# CYBLE_222014_01 register map
File version: 0.1
PRoC BLE
Registers are 32-bit, read-write, no defined reset value unless marked. A register's access mark holds for its fields unless they carry their own. Offsets are from the block's base; lines under a group give offsets from that group; [hi:lo] are bit positions; {n}, {i} and the like mark numbered series; 'fields as' and 'values as' point back to an identical list; <NAME> marks a mode.

## Memory map
0x00000000 Uart — Serial Communication Block
0x00000000 Pwm
0x40000000 DMAC — DMAC Registers

## Pwm
Base 0x00000000
0x400F0022 Pwm__COMPARE1 8-bit — UDB.D0 - Assigned Compare1 Value
0x400F0032 Pwm__COMPARE2 8-bit — UDB.D1 - Assigned Compare2 Value
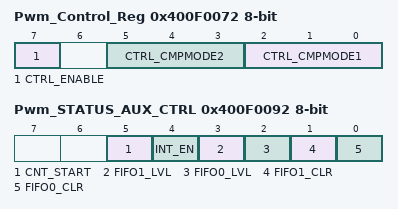
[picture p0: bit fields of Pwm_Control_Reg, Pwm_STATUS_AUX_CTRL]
0x400F0072 Pwm_Control_Reg 8-bit — UDB Control Register - Assigned Control Register Value
  [7] CTRL_ENABLE — Enable the PWM
  [5:3] CTRL_CMPMODE2 — Compare mode 2
  [2:0] CTRL_CMPMODE1 — Compare mode 1
0x400F0092 Pwm_STATUS_AUX_CTRL 8-bit — UDB Auxilliary Control Register
  [5] CNT_START — FIFO0 clear
    0=E_CNT_START0 (Disable counter); 1=E_CNT_START1 (Enable counter)
  [4] INT_EN
    0=E_INT_EN0 (Interrupt disabled); 1=E_INT_EN1 (Interrupt enabled)
  [3] FIFO1_LVL — FIFO level
    0=E_FIFO_LVL_0 (FIFO LVL: input mode: FIFO not full; output mode: FIFO not empty); 1=E_FIFO_LVL_1 (FIFO LVL: input mode: FIFO at least 1/2 empty; output mode: FIFO at least 1/2 full)
  [2] FIFO0_LVL — FIFO level
    values as FIFO1_LVL
  [1] FIFO1_CLR — FIFO1 clear
    0=E_FIFO_CLR_0 (Normal FIFO operation); 1=E_FIFO_CLR_1 (Clear FIFO state)
  [0] FIFO0_CLR — FIFO0 clear
    values as FIFO1_CLR

## DMAC — DMAC Registers
Base 0x40000000
0x101000 DMAC_CTL — DMA controller control register
  [31] ENABLED — Global DMAC enable
    0=Disabled (DMA controller is disabled.); 1=Enabled (DMA controller is enabled.)
0x101010 DMAC_STATUS — DMA controller status register
  [31] PING_PONG ro — Specifies whether the PING descriptor ('0') or PONG descriptor ('1') of the channel is currently in use.
    0=DESCR0 (Descriptor 0 (PING) is currently in use.); 1=DESCR1 (Descriptor 1 (PONG) is currently in use.)
  [31] ACTIVE ro — Specifies if there is a currently active (pending) channel in the data transfer engine.
    0=IDLE (No currently active channel.); 1=ACTIVE (Currently active channel.)
  [29:28] PRIO ro — Specifies the priority of the currently active channel.
  [26:24] STATE ro — State of the data transfer engine.
    0=IDLE (Idle state when the DMA is not active.); 1=LOAD_DESCR (The DMA is loading the descriptor to the DMA transfer engine.); 2=LOAD_SRC (The DMA is getting the value from the source location.); 3=STORE_DST (The DMA is storing the value at the destination location.); 4=STORE_DESCR (The DMA is updating the descriptors after completion of transfer.); 5=WAIT_TRIG_DEACT (The DMA is waiting for the level sensitive trigger to deactivate.); 6=STORE_ERROR (There was an error during the transaction and the DMA is writing the error code to the channel status register.)
  [20:16] CH_ADDR ro — Specifies the channel number of the currently active channel. For example, if channel 7 is active, DMAC_STATUS.ACTIVE is '1' and STATUS.CH_ADDR is '7'.
  [15:0] DATA_NR ro — Specifies the index of the currently active data transfer. This value increases from '0' to the DATA_NR field specified of the currently active descriptor control word.
0x101014 DMAC_STATUS_SRC_ADDR — Source address currently being used by the DMA controller
  [31:0] ADDR ro — The source address currently being used by the DMA transfer engine. This field is provided for debug purposes. Note while reading the DMAC_STATUS, DMAC_STATUS_SRC_ADDR and DMAC_STATUS_DST_ADDR registers, the transfer engine may have advanced after one or more of these reads. Meaning the register values may not be related to each other.
0x101018 DMAC_STATUS_DST_ADDR — Destination address currently being used by the DMA controller
  [31:0] ADDR ro — The destination address currently being used by the DMA transfer engine. This field is provided for debug purposes. Note while reading the DMAC_STATUS, DMAC_STATUS_SRC_ADDR and DMAC_STATUS_DST_ADDR registers, the transfer engine may have advanced after one or more of these reads. Meaning the register values may not be related to each other.
0x10101C DMAC_STATUS_CH_ACT — Channel activation status
  [31:0] CH ro — Channel activation status. Bit i is associated to channel i. Software reads this field to get information on all actively pending channels (either in pending or in the data transfer engine).
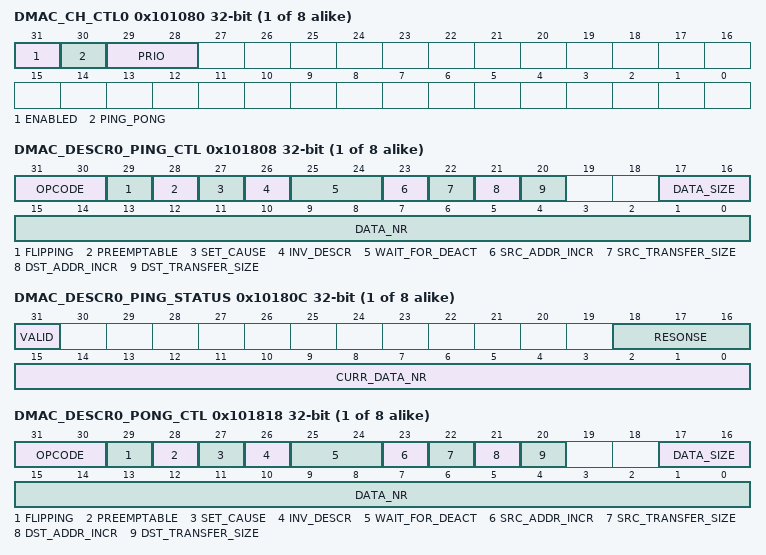
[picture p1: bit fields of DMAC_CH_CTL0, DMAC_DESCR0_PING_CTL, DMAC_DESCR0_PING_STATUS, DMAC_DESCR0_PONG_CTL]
{0x101080+4i} DMAC_CH_CTL{i} (i=0..7) — DMA channel {i} control register
  [31] ENABLED — Channel enable control.
    0=Disabled (Channel is currently disabled.); 1=Enabled (Channel is currently enabled.)
  [30] PING_PONG — Identifies the descriptor structure that is currently in use by the DMA controller.
    values as DMAC_STATUS.PING_PONG
  [29:28] PRIO — Channel priority. Priority can be 0,1,2 or 3. 0 is the highest.
0x1017F0 DMAC_INTR — Interrupt register
  [31:0] CH — Set to '1', when event is detected. Write INTR field with '1', to clear bit. Write INTR_SET field with '1', to set bit.
0x1017F4 DMAC_INTR_SET — Interrupt set register
  [31:0] CH — Write INTR_SET field with '1' to set corresponding INTR field (a write of '0' has no effect).
0x1017F8 DMAC_INTR_MASK — Interrupt mask register
  [31:0] CH — Mask for corresponding field in INTR register.
0x1017FC DMAC_INTR_MASKED — Interrupt masked register
  [31:0] CH ro — Bitwise AND between the interrupt reguest (INTR) and mask (INTR_MASK) registers.
{0x101800+0x20*i} DMAC_DESCR{i}_PING_SRC (i=0..7) — Descriptor 0 source address location for channel {i}
  [31:0] SRC — Source address.
{0x101804+0x20*i} DMAC_DESCR{i}_PING_DST (i=0..7) — Descriptor 0 destination address location for channel {i}
  [31:0] DST — Destination address.
{0x101808+0x20*i} DMAC_DESCR{i}_PING_CTL (i=0..7) — Descriptor 0 control register for channel {i}
  [31:30] OPCODE — Specifies how the DMA reacts to a trigger event.
    0=SINGLE_DATA_ELEMENT (A single trigger initiates a single data element transfer. This opcode specifies a transfer of a single data element. The current descriptor is completed when the amount of transferred single data elements equals the programmed buffer size (DATA_NR+1).); 1=ENTIRE_DESCRIPTOR (A single trigger initiates an entire descriptor transfer. This opcode specifies a transfer of DATA_NR+1 data elements as specified by the current descriptor structure. The current descriptor is completed when its data transfer is completed.); 2=ENTIRE_DESCRIPTOR_CHAIN (A single trigger initiates a descriptor list transfer. This opcode specifies a transfer of DATA_NR+1 data elements as specified by the current descriptor structure and by successive valid descriptors. The current descriptor is completed when its data transfer is completed. This OPCODE relies on FLIPPING to be set to '1', such that the CHi_CTL.PING_PONG field is flipped/inverted and the successive descriptor is used. This continues for as long as the successive descriptor is valid. Note that as the HW is using the PING/PONG descriptor, the SW can prepare the alternate PONG/PING descriptor. The interrupt mechanism is used by HW to convey to the SW that the current descriptor is completed (and can be prepared for a successive transfer).)
  [29] FLIPPING — If set, on completion of the current descriptor structure, the current descriptor identifier is flipped/inverted. In DMA mode, descriptor list transfer, flipping of the current descriptor identifier can be used to construct a linked list of descriptor structures.
  [28] PREEMPTABLE — If set, the transfer is preemptable. Multi data element transfers are constructed out of multiple single data element load (from the source location) and store (to the destination location) sequences. This field allows higher priority activated channels to preempt the current transfer in between these atomic (load, store) sequences. Preemption will NOT deactivate the current channel. As a result, after completion of a higher priority activated channel, the current channel is rescheduled.
  [27] SET_CAUSE — If set, the interrupt bit of the channel is set to '1' on completion of the current descriptor structure.
  [26] INV_DESCR — If set, the VALID bit of the descriptor's STATUS word is set to '0' on completion of the current descriptor structure.
  [25:24] WAIT_FOR_DEACT — Specifies whether the data transfer engine should wait for the channel to be deactivated; i.e. the selected system trigger is not active. This field is used to synchronize the controller's data transfer(s) with the agent that generated the trigger. This field is ONLY used at the completion of an opcode. E.g., a FIFO indicates that it is empty and it needs a new data sample. The agent removes the trigger ONLY when the data sample has been written by the transfer engine AND received by the agent. Furthermore, the agent's trigger may be delayed by a few cycles before it reaches the DW/DMA controller. This field is used for level sensitive trigger, which reflect state (pulse sensitive triggers should have this field set to '0'). The wait cycles incurred by this field reduce DW/DMA controller performance.
    0=PULSE (Do not wait for de-activation (for pulse sensitive triggers).); 1=LEVEL_FOUR (Wait for up to 4 cycles.); 2=LEVEL_EIGHT (Wait for up to 8 cycles.); 3=LEVEL_UNKNOWN (Wait indefinitely. This option may result in DMA controller lockup if the system trigger is not de-activated by the source agent.)
  [23] SRC_ADDR_INCR — Specifies whether the source address is incremented by the SRC_TRANSFER_SIZE after the transfer of each data element.
    0=INC_NONE (No address increment.); 1=INC_SRC_ADDR (Increment the source address.)
  [22] SRC_TRANSFER_SIZE — Specifies the bus transfer size to the source location.
    0=DATA_SIZE (As specified by DATA_SIZE field.); 1=WORD (Word (4 bytes).)
  [21] DST_ADDR_INCR — Specifies whether the destination address is incremented by the DST_TRANSFER_SIZE after the transfer of each data element.
    0=INC_NONE (No address increment.); 1=INC_DST_ADDR (Increment the destination address.)
  [20] DST_TRANSFER_SIZE — Specifies the bus transfer size to the destination location.
    values as SRC_TRANSFER_SIZE
  [17:16] DATA_SIZE — Specifies the data element size.
    0=BYTE (1 byte.); 1=HALFWORD (Halfword (2 bytes).); 2=WORD (Word (4 bytes).)
  [15:0] DATA_NR — Number of data elements this descriptor transfers. A value of N results in a transfer of N+1 data elements.
{0x10180C+0x20*i} DMAC_DESCR{i}_PING_STATUS (i=0..7) — Descriptor 0 status register for channel {i}
  [31] VALID — Descriptor validity status. Hardware set this field to '0' when a descriptor is done, but only if CONTROL.INV_DESCR is '1'. Software sets this field to '1' when a descriptor is initialized.
    0=INVALID (Invalid, cannot be used for a data transfer. An attempt to use this descriptor for a data transfer will result in an INVALID_DESCR response code and the interrupt cause bit is set to '1'.); 1=VALID
  [18:16] RESONSE — Response code (the first two codes NO_ERROR and DONE are the result of normal behavior, the other codes are the result of erroneous behavior).
    0=NO_ERROR (No error. Setting this response does NOT set the interrupt bit to '1'. STATUS.VALID is NOT affected. CHx_CTL.ENABLED is NOT affected. CHx_CTL.PING_PONG is not updated. This response is used for an unused or not completed descriptor. Software should set the RESPONSE field to '0'/NO_ERROR during descriptor initialization.); 1=DONE (Descriptor is done (without errors). Setting this response sets the interrupt cause bit to '1' if CONTROL.SET_CAUSE is '1'. STATUS.VALID is set to '0' if CONTROL.INV_DESCR is '1'. CHx_CTL.ENABLED is NOT affected. CHx_CTL.PING_PONG is updated if CONTROL.FLIPPING is '1'.); 2=SRC_BUS_ERROR (Bus error while loading data from the source location. Setting this response sets the interrupt cause bit to '1'. STATUS.VALID is set '0'. CHx_CTL.ENABLED is set to '0'. CHx_CTL.PING_PONG is not updated (it identifies the descriptor that caused the error).); 3=DST_BUS_ERROR (Bus error while storing data to the destination location. Setting this response sets the interrupt cause bit to '1'. STATUS.VALID is set '1'. CHx_CTL.ENABLED is set to '0'. CHx_CTL.PING_PONG is not updated (it identifies the descriptor that caused the error).); 4=SRC_MISAL (Misalignment of source address. This occurs on a 16-bit bus transfer that is not 2-byte aligned or on a 32-bit bus transfer that is not 4-byte aligned. Setting this response sets the interrupt cause bit to '1'. STATUS.VALID is set '0'. CHx_CTL.ENABLED is set to '0'. CHx_CTL.PING_PONG is not updated (it identifies the descriptor that caused the error).); 5=DST_MISAL (Misalignment of destination address. This occurs on a 16-bit bus transfer that is not 2-byte aligned or on a 32-bit bus transfer that is not 4-byte aligned. Setting this response sets the interrupt cause bit to '1'. STATUS.VALID is set '0'. CHx_CTL.ENABLED is set to '0'. CHx_CTL.PING_PONG is not updated (it identifies the descriptor that caused the error).); 6=INVALID (Invalid descriptor (STATUS.VALID is '0'). This occurs when an activated channel has an invalid descriptor. CHx_CTL.ENABLED is set to '0'. CHx_CTL.PING_PONG is not updated (it identifies the descriptor that caused the error).)
  [15:0] CURR_DATA_NR — Specifies the index of the current data transfer. This value increases from 0 to CONTROL.DATA_NR. HW sets this field: ? - When a descriptor is done (RESPONSE is DONE), the field is set to '0' when PING_CTL.INV_DESCR is '0' and the field is set to PING_CTL.DATA_NR when PING_CTL.INV_DESCR is '1'. ? - When a descriptor is not done (RESPONSE is NO_ERROR), the field reflects the progress of a data transfer. ? - In case of erroneous behavior (RESPONSE is neither DONE or NO_ERROR), the field is not updated, but keeps its value to ease debugging. ? HW only modifies this field for an active descriptor (STATUS.VALID to be '1'). At descriptor initialization, SW should set this field to '0'. ? This field allows software to read the progress of the data transfer. Note that SRC.ADDR and DST.ADDR represent base addresses and are not modified during data transfer. However, STATUS.CURR_DATA_NR is modified during data transfer and provides an offset wrt. the base addresses.
{0x101810+0x20*i} DMAC_DESCR{i}_PONG_SRC (i=0..7) — Descriptor 1 source address location for channel {i}
  [31:0] SRC — Source address.
{0x101814+0x20*i} DMAC_DESCR{i}_PONG_DST (i=0..7) — Descriptor 1 destination address location for channel {i}
  [31:0] DST — Destination address.
{0x101818+0x20*i} DMAC_DESCR{i}_PONG_CTL (i=0..7) — Descriptor 1 control register for channel {i}
  fields as DMAC_DESCR0_PING_CTL
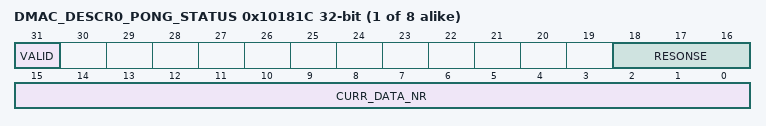
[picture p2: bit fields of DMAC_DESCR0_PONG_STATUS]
{0x10181C+0x20*i} DMAC_DESCR{i}_PONG_STATUS (i=0..7) — Descriptor 1 status register for channel {i}
  fields as DMAC_DESCR0_PING_STATUS
